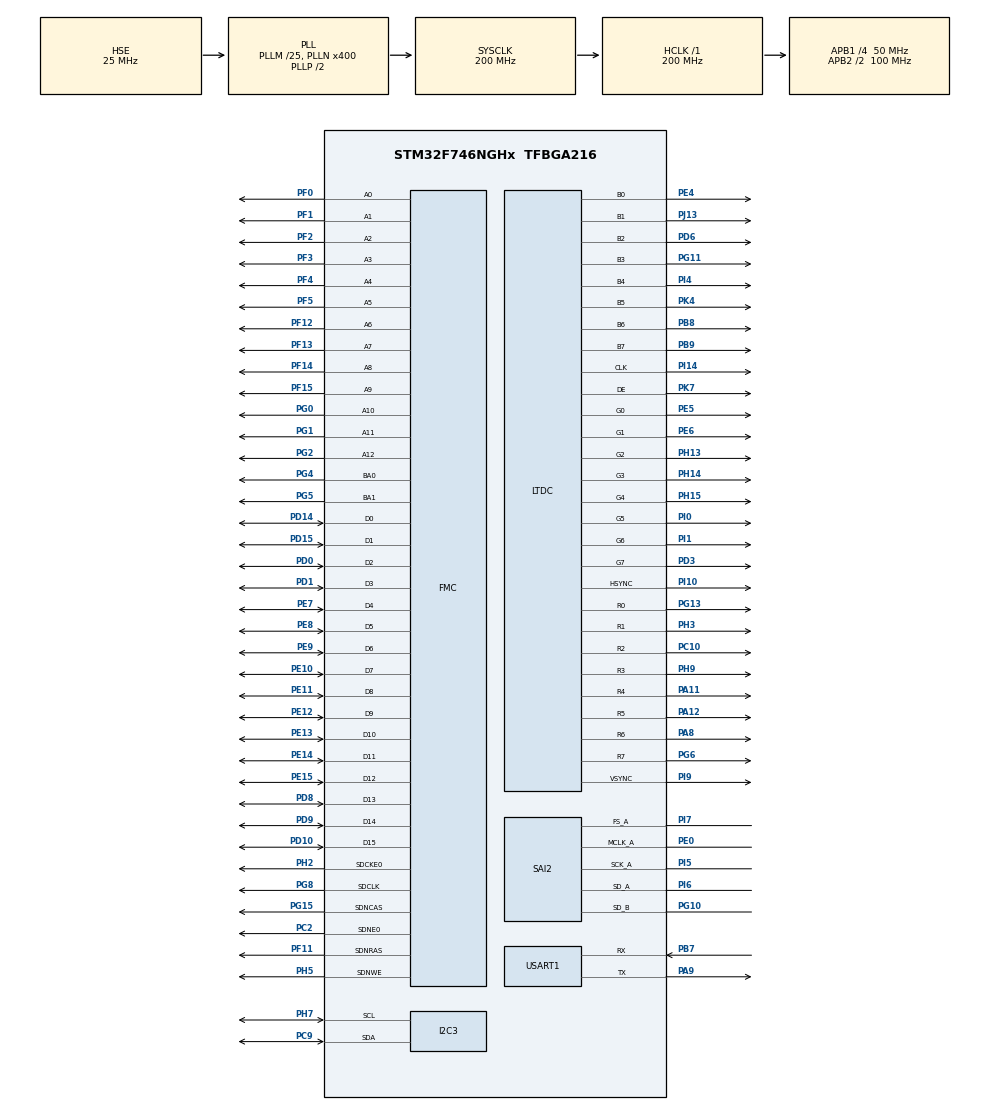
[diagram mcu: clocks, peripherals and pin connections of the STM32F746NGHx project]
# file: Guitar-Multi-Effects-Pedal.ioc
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Dma.Request0=SAI2_A
Dma.Request1=SAI2_B
Dma.SAI2_A.0.Direction=DMA_MEMORY_TO_PERIPH
Dma.SAI2_A.0.FIFOMode=DMA_FIFOMODE_DISABLE
Dma.SAI2_A.0.Instance=DMA2_Stream4
Dma.SAI2_A.0.MemDataAlignment=DMA_MDATAALIGN_BYTE
Dma.SAI2_A.0.MemInc=DMA_MINC_ENABLE
Dma.SAI2_A.0.Mode=DMA_CIRCULAR
Dma.SAI2_A.0.PeriphDataAlignment=DMA_PDATAALIGN_BYTE
Dma.SAI2_A.0.PeriphInc=DMA_PINC_DISABLE
Dma.SAI2_A.0.Priority=DMA_PRIORITY_HIGH
Dma.SAI2_B.1.Direction=DMA_PERIPH_TO_MEMORY
Dma.SAI2_B.1.FIFOMode=DMA_FIFOMODE_DISABLE
Dma.SAI2_B.1.Instance=DMA2_Stream6
Dma.SAI2_B.1.MemDataAlignment=DMA_MDATAALIGN_HALFWORD
Dma.SAI2_B.1.MemInc=DMA_MINC_ENABLE
Dma.SAI2_B.1.Mode=DMA_CIRCULAR
Dma.SAI2_B.1.PeriphDataAlignment=DMA_PDATAALIGN_HALFWORD
Dma.SAI2_B.1.PeriphInc=DMA_PINC_DISABLE
Dma.SAI2_B.1.Priority=DMA_PRIORITY_HIGH
I2C3.Timing=0x00C0EAFF
Mcu.Family=STM32F7
Mcu.Name=STM32F746NGHx
Mcu.Package=TFBGA216
NVIC.DMA2_Stream4_IRQn=true\:0\:0\:false\:false\:true\:false\:true\:true
NVIC.DMA2_Stream6_IRQn=true\:0\:0\:false\:false\:true\:false\:true\:true
NVIC.PriorityGroup=NVIC_PRIORITYGROUP_4
PA11.Mode=RGB888
PA11.Signal=LTDC_R4
PA12.Mode=RGB888
PA12.Signal=LTDC_R5
PA13.Mode=Serial_Wire
PA13.Signal=SYS_JTMS-SWDIO
PA14.Mode=Serial_Wire
PA14.Signal=SYS_JTCK-SWCLK
PA8.Mode=RGB888
PA8.Signal=LTDC_R6
PA9.Mode=Asynchronous
PA9.Signal=USART1_TX
PB7.Mode=Asynchronous
PB7.Signal=USART1_RX
PB8.Mode=RGB888
PB8.Signal=LTDC_B6
PB9.Mode=RGB888
PB9.Signal=LTDC_B7
PC10.Mode=RGB888
PC10.Signal=LTDC_R2
PC14/OSC32_IN.Mode=LSE-External-Oscillator
PC14/OSC32_IN.Signal=RCC_OSC32_IN
PC15/OSC32_OUT.Mode=LSE-External-Oscillator
PC15/OSC32_OUT.Signal=RCC_OSC32_OUT
PC2.Mode=SdramChipSelect1_1
PC2.Signal=FMC_SDNE0
PC9.Mode=I2C
PC9.Signal=I2C3_SDA
PD0.Signal=FMC_D2_DA2
PD1.Signal=FMC_D3_DA3
PD10.Signal=FMC_D15_DA15
PD14.Signal=FMC_D0_DA0
PD15.Signal=FMC_D1_DA1
PD3.Mode=RGB888
PD3.Signal=LTDC_G7
PD6.Mode=RGB888
PD6.Signal=LTDC_B2
PD8.Signal=FMC_D13_DA13
PD9.Signal=FMC_D14_DA14
PE0.Mode=SAI_A_MasterWithClock
PE0.Signal=SAI2_MCLK_A
PE10.Signal=FMC_D7_DA7
PE11.Signal=FMC_D8_DA8
PE12.Signal=FMC_D9_DA9
PE13.Signal=FMC_D10_DA10
PE14.Signal=FMC_D11_DA11
PE15.Signal=FMC_D12_DA12
PE4.Mode=RGB888
PE4.Signal=LTDC_B0
PE5.Mode=RGB888
PE5.Signal=LTDC_G0
PE6.Mode=RGB888
PE6.Signal=LTDC_G1
PE7.Signal=FMC_D4_DA4
PE8.Signal=FMC_D5_DA5
PE9.Signal=FMC_D6_DA6
PF0.Signal=FMC_A0
PF1.Signal=FMC_A1
PF11.Signal=FMC_SDNRAS
PF12.Signal=FMC_A6
PF13.Signal=FMC_A7
PF14.Signal=FMC_A8
PF15.Signal=FMC_A9
PF2.Signal=FMC_A2
PF3.Signal=FMC_A3
PF4.Signal=FMC_A4
PF5.Signal=FMC_A5
PG0.Signal=FMC_A10
PG1.Signal=FMC_A11
PG10.Mode=SAI_B_SyncSlave
PG10.Signal=SAI2_SD_B
PG11.Mode=RGB888
PG11.Signal=LTDC_B3
PG13.Mode=RGB888
PG13.Signal=LTDC_R0
PG15.Signal=FMC_SDNCAS
PG2.Signal=FMC_A12
PG4.Signal=FMC_A14_BA0
PG5.Signal=FMC_A15_BA1
PG6.Mode=RGB888
PG6.Signal=LTDC_R7
PG8.Signal=FMC_SDCLK
PH0/OSC_IN.Mode=HSE-External-Oscillator
PH0/OSC_IN.Signal=RCC_OSC_IN
PH1/OSC_OUT.Mode=HSE-External-Oscillator
PH1/OSC_OUT.Signal=RCC_OSC_OUT
PH13.Mode=RGB888
PH13.Signal=LTDC_G2
PH14.Mode=RGB888
PH14.Signal=LTDC_G3
PH15.Mode=RGB888
PH15.Signal=LTDC_G4
PH2.Mode=SdramChipSelect1_1
PH2.Signal=FMC_SDCKE0
PH3.Mode=RGB888
PH3.Signal=LTDC_R1
PH5.Signal=FMC_SDNWE
PH7.Mode=I2C
PH7.Signal=I2C3_SCL
PH9.Mode=RGB888
PH9.Signal=LTDC_R3
PI0.Mode=RGB888
PI0.Signal=LTDC_G5
PI1.Mode=RGB888
PI1.Signal=LTDC_G6
PI10.Mode=RGB888
PI10.Signal=LTDC_HSYNC
PI14.Mode=RGB888
PI14.Signal=LTDC_CLK
PI4.Mode=RGB888
PI4.Signal=LTDC_B4
PI5.Mode=SAI_A_MasterWithClock
PI5.Signal=SAI2_SCK_A
PI6.Mode=SAI_A_MasterWithClock
PI6.Signal=SAI2_SD_A
PI7.Mode=SAI_A_MasterWithClock
PI7.Signal=SAI2_FS_A
PI9.Mode=RGB888
PI9.Signal=LTDC_VSYNC
PJ13.Mode=RGB888
PJ13.Signal=LTDC_B1
PK4.Mode=RGB888
PK4.Signal=LTDC_B5
PK7.Mode=RGB888
PK7.Signal=LTDC_DE
ProjectManager.HeapSize=0x200
ProjectManager.StackSize=0x400
ProjectManager.TargetToolchain=STM32CubeIDE
RCC.AHBFreq_Value=200000000
RCC.APB1CLKDivider=RCC_HCLK_DIV4
RCC.APB1Freq_Value=50000000
RCC.APB1TimFreq_Value=100000000
RCC.APB2CLKDivider=RCC_HCLK_DIV2
RCC.APB2Freq_Value=100000000
RCC.APB2TimFreq_Value=200000000
RCC.CortexFreq_Value=200000000
RCC.HCLKFreq_Value=200000000
RCC.HSE_VALUE=25000000
RCC.HSI_VALUE=16000000
RCC.PLLI2SN=100
RCC.PLLM=25
RCC.PLLN=400
RCC.PLLSAIN=384
RCC.PLLSAIQ=8
RCC.PLLSAIR=5
RCC.PLLSAIRDiv=RCC_PLLSAIDIVR_8
RCC.PLLSourceVirtual=RCC_PLLSOURCE_HSE
RCC.SYSCLKFreq_VALUE=200000000
RCC.SYSCLKSource=RCC_SYSCLKSOURCE_PLLCLK
RCC.USBFreq_Value=200000000
RCC.VCOOutputFreq_Value=400000000
SAI2.AudioFrequency-SAI_A_MasterWithClock=SAI_AUDIO_FREQUENCY_48K
SAI2.DataSize-SAI_A_MasterWithClock=SAI_DATASIZE_16
SAI2.DataSize-SAI_B_SyncSlave=SAI_DATASIZE_16
SAI2.ErrorAudioFreq-SAI_A_MasterWithClock=-2.34 %
SAI2.FrameLength-SAI_A_MasterWithClock=32
SAI2.FrameLength-SAI_B_SyncSlave=32
SAI2.Instance-SAI_A_MasterWithClock=SAI$Index_Block_A
SAI2.Instance-SAI_B_SyncSlave=SAI$Index_Block_B
SAI2.MClockEnable-SAI_A_MasterWithClock=SAI_MASTERCLOCK_ENABLE
SAI2.RealAudioFreq-SAI_A_MasterWithClock=46.875 KHz
SAI2.VirtualMode-SAI_A_MasterWithClock=VM_MASTER
SAI2.VirtualMode-SAI_B_SyncSlave=VM_SLAVE
SH.FMC_A0.0=FMC_A0,13b-sda1
SH.FMC_A1.0=FMC_A1,13b-sda1
SH.FMC_A10.0=FMC_A10,13b-sda1
SH.FMC_A11.0=FMC_A11,13b-sda1
SH.FMC_A12.0=FMC_A12,13b-sda1
SH.FMC_A14_BA0.0=FMC_BA0,FourSdramBanks1
SH.FMC_A15_BA1.0=FMC_BA1,FourSdramBanks1
SH.FMC_A2.0=FMC_A2,13b-sda1
SH.FMC_A3.0=FMC_A3,13b-sda1
SH.FMC_A4.0=FMC_A4,13b-sda1
SH.FMC_A5.0=FMC_A5,13b-sda1
SH.FMC_A6.0=FMC_A6,13b-sda1
SH.FMC_A7.0=FMC_A7,13b-sda1
SH.FMC_A8.0=FMC_A8,13b-sda1
SH.FMC_A9.0=FMC_A9,13b-sda1
SH.FMC_D0_DA0.0=FMC_D0,sd-16b-d1
SH.FMC_D10_DA10.0=FMC_D10,sd-16b-d1
SH.FMC_D11_DA11.0=FMC_D11,sd-16b-d1
SH.FMC_D12_DA12.0=FMC_D12,sd-16b-d1
SH.FMC_D13_DA13.0=FMC_D13,sd-16b-d1
SH.FMC_D14_DA14.0=FMC_D14,sd-16b-d1
SH.FMC_D15_DA15.0=FMC_D15,sd-16b-d1
SH.FMC_D1_DA1.0=FMC_D1,sd-16b-d1
SH.FMC_D2_DA2.0=FMC_D2,sd-16b-d1
SH.FMC_D3_DA3.0=FMC_D3,sd-16b-d1
SH.FMC_D4_DA4.0=FMC_D4,sd-16b-d1
SH.FMC_D5_DA5.0=FMC_D5,sd-16b-d1
SH.FMC_D6_DA6.0=FMC_D6,sd-16b-d1
SH.FMC_D7_DA7.0=FMC_D7,sd-16b-d1
SH.FMC_D8_DA8.0=FMC_D8,sd-16b-d1
SH.FMC_D9_DA9.0=FMC_D9,sd-16b-d1
SH.FMC_SDCLK.0=FMC_SDCLK,13b-sda1
SH.FMC_SDNCAS.0=FMC_SDNCAS,13b-sda1
SH.FMC_SDNRAS.0=FMC_SDNRAS,13b-sda1
SH.FMC_SDNWE.0=FMC_SDNWE,13b-sda1
USART1.VirtualMode-Asynchronous=VM_ASYNC
VP_DMA2D_VS_DMA2D.Mode=DMA2D_Activate
VP_TIM1_VS_ClockSourceINT.Mode=Internal
board=STM32F746G-DISCO

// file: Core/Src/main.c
/* USER CODE BEGIN Header */
/**
  ******************************************************************************
  * @file           : main.c
  * @brief          : Initializes system, calls Audio_Peripheral_Init(), handles the main loop logic.
  ******************************************************************************
  * @attention
  *
  * Copyright (c) 2024 STMicroelectronics.
  * All rights reserved.
  *
  * This software is licensed under terms that can be found in the LICENSE file
  * in the root directory of this software component.
  * If no LICENSE file comes with this software, it is provided AS-IS.
  *
  ******************************************************************************
  */

/* Pseudocode:
 *
 *  Set up buffers:
 *
 *
 *
 *  CODEC ADC -->  SAI2B (SAI receiving subblock) -> input_buffer[N/4] (16 bit), x_in_temp[N] (32 bit float conversion), x_in[N] input signal block, (DSP happens here), x_out_temp[2*N] circular buffer of output signal, output_buffer[N/4] (16 bit) --> SAI2A (SAI transmitting subblock) --> CODEC DAC
 *
 * Initialize audio input and audio output lines on audio CODEC. Use BSP_AUDIO_OUT_Init and BSP_AUDIO_IN_InitEx function and the following audio devices:  INPUT_DEVICE_INPUT_LINE_1 , OUTPUT_DEVICE_HEADPHONE
 *
 *
 *
 *Buffer Size (bytes)=Number of Samples×Number of Channels×Bytes per Sample
 *
 *
 *
 *
 */
/* USER CODE END Header */
#include "main.h"

/* USER CODE BEGIN Includes */

#include "stm32f7xx_hal.h"
#include "wm8994.h"
#include "stm32746g_discovery_audio.h"
#include <string.h>

/* USER CODE END Includes */

/* USER CODE BEGIN PD */

#define BUFFER_SIZE  512

// Define the SAI handles
SAI_HandleTypeDef hsai_Out;
SAI_HandleTypeDef hsai_In;

// DMA handle
DMA_HandleTypeDef hdma_sai_rx;
DMA_HandleTypeDef hdma_sai_tx;

/* USER CODE END PD */

DMA2D_HandleTypeDef hdma2d;

I2C_HandleTypeDef hi2c3;

LTDC_HandleTypeDef hltdc;

SAI_HandleTypeDef hsai_BlockA2;
SAI_HandleTypeDef hsai_BlockB2;
DMA_HandleTypeDef hdma_sai2_a;
DMA_HandleTypeDef hdma_sai2_b;

TIM_HandleTypeDef htim1;

UART_HandleTypeDef huart1;

SDRAM_HandleTypeDef hsdram1;

/* USER CODE BEGIN PV */
extern SAI_HandleTypeDef haudio_out_sai, haudio_in_sai;

int16_t input_data[BUFFER_SIZE];
int16_t processed_data[BUFFER_SIZE];
int16_t output_data[BUFFER_SIZE];

static volatile int16_t *inBufPtr;
static volatile int16_t *procBufPtr = &processed_data[0];
static volatile int16_t *outBufPtr = &output_data[0];

uint8_t dataReadyFlag;

/* USER CODE END PV */

void SystemClock_Config(void);
void PeriphCommonClock_Config(void);
static void MX_GPIO_Init(void);
static void MX_DMA_Init(void);
static void MX_SAI2_Init(void);
static void MX_USART1_UART_Init(void);
static void MX_TIM1_Init(void);
static void MX_DMA2D_Init(void);
static void MX_LTDC_Init(void);
static void MX_FMC_Init(void);
static void MX_I2C3_Init(void);
/* USER CODE BEGIN PFP */

void processData(int16_t *inBufPtr, int16_t *outBufPtr, uint16_t size);
static void fill_buffer_with_square_wave(int16_t *buf, uint32_t num_samples);

/* USER CODE END PFP */

/* USER CODE BEGIN 0 */
void BSP_AUDIO_IN_HalfTransfer_CallBack()
{
	// Process the first half of the input buffer
		processData(&input_data[0], &processed_data[0], BUFFER_SIZE / 2);
		dataReadyFlag = 1;
}

void BSP_AUDIO_IN_TransferComplete_CallBack()
{
	processData(&input_data[BUFFER_SIZE / 2], &processed_data[BUFFER_SIZE / 2], BUFFER_SIZE / 2);
	dataReadyFlag = 1;
}

void BSP_AUDIO_OUT_HalfTransfer_CallBack()
{
	memcpy(&output_data[0], &processed_data[0], BUFFER_SIZE / 2 * sizeof(int16_t));
}

void BSP_AUDIO_OUT_TransferComplete_CallBack()
{
	memcpy(&output_data[BUFFER_SIZE / 2], &processed_data[BUFFER_SIZE / 2], BUFFER_SIZE / 2 * sizeof(int16_t));
}

/* USER CODE END 0 */

int main(void)
{

  /* MCU Configuration--------------------------------------------------------*/

  /* Reset of all peripherals, Initializes the Flash interface and the Systick. */
  HAL_Init();

  /* Configure the system clock */
  SystemClock_Config();

  /* Configure the peripherals common clocks */
  PeriphCommonClock_Config();

  /* Initialize all configured peripherals */
  MX_GPIO_Init();
  MX_DMA_Init();
  MX_SAI2_Init();
  MX_USART1_UART_Init();
  MX_TIM1_Init();
  MX_DMA2D_Init();
  MX_LTDC_Init();
  MX_FMC_Init();
  MX_I2C3_Init();
  /* USER CODE BEGIN 2 */
  Display_Init();
  if (wm8994_Init(AUDIO_I2C_ADDRESS, INPUT_DEVICE_INPUT_LINE_1 | OUTPUT_DEVICE_HEADPHONE , 80, SAI_AUDIO_FREQUENCY_48K)==0)
  {
	  Display_Draw_Text("Codec initialized", 0, 10);
  }
  HAL_Delay(50);
  // Start audio input (SAI Receive) and output (SAI Transmit) using DMA
 // HAL_StatusTypeDef statusTx = HAL_SAI_Transmit_DMA(&hsai_BlockA2, (uint8_t *)output_data, BUFFER_SIZE);
 // HAL_StatusTypeDef statusRx = HAL_SAI_Receive_DMA(&hsai_BlockB2, (uint8_t *)input_data, BUFFER_SIZE);

   //Display_Draw_Text("Codec is not recording", 0, 60);

 /* if (HAL_SAI_Receive_DMA(&hsai_BlockB2, (uint8_t *)input_data, BUFFER_SIZE) == HAL_OK)
  {
	  Display_Draw_Text("SAI Recieve Setup", 0, 30);
  }
  else{
	  Display_Draw_Text("SAI Recieve Not Setup", 0, 30);
  }
*/

  if (HAL_SAI_Transmit_DMA(&hsai_BlockA2, (uint8_t *)output_data, BUFFER_SIZE) == HAL_OK)
  {
	  Display_Draw_Text("SAI Transmit Setup", 0, 50);
  }
  else{
	  Display_Draw_Text("SAI Transmit Not Setup", 0, 50);
  }

  dataReadyFlag = 0;

  fill_buffer_with_square_wave(input_data, BUFFER_SIZE);

  /* USER CODE END 2 */

  /* Infinite loop */
  /* USER CODE BEGIN WHILE */
  while (1)
  {
	  if (dataReadyFlag){

		  // Reset the flag after processing
	dataReadyFlag = 0;

	  }

    /* USER CODE END WHILE */

  }
}

void SystemClock_Config(void)
{
  RCC_OscInitTypeDef RCC_OscInitStruct = {0};
  RCC_ClkInitTypeDef RCC_ClkInitStruct = {0};

  /** Configure LSE Drive Capability
  */
  HAL_PWR_EnableBkUpAccess();

  /** Configure the main internal regulator output voltage
  */
  __HAL_RCC_PWR_CLK_ENABLE();
  __HAL_PWR_VOLTAGESCALING_CONFIG(PWR_REGULATOR_VOLTAGE_SCALE1);

  /** Initializes the RCC Oscillators according to the specified parameters
  * in the RCC_OscInitTypeDef structure.
  */
  RCC_OscInitStruct.OscillatorType = RCC_OSCILLATORTYPE_HSE;
  RCC_OscInitStruct.HSEState = RCC_HSE_ON;
  RCC_OscInitStruct.PLL.PLLState = RCC_PLL_ON;
  RCC_OscInitStruct.PLL.PLLSource = RCC_PLLSOURCE_HSE;
  RCC_OscInitStruct.PLL.PLLM = 25;
  RCC_OscInitStruct.PLL.PLLN = 400;
  RCC_OscInitStruct.PLL.PLLP = RCC_PLLP_DIV2;
  RCC_OscInitStruct.PLL.PLLQ = 2;
  if (HAL_RCC_OscConfig(&RCC_OscInitStruct) != HAL_OK)
  {
    Error_Handler();
  }

  /** Activate the Over-Drive mode
  */
  if (HAL_PWREx_EnableOverDrive() != HAL_OK)
  {
    Error_Handler();
  }

  /** Initializes the CPU, AHB and APB buses clocks
  */
  RCC_ClkInitStruct.ClockType = RCC_CLOCKTYPE_HCLK|RCC_CLOCKTYPE_SYSCLK
                              |RCC_CLOCKTYPE_PCLK1|RCC_CLOCKTYPE_PCLK2;
  RCC_ClkInitStruct.SYSCLKSource = RCC_SYSCLKSOURCE_PLLCLK;
  RCC_ClkInitStruct.AHBCLKDivider = RCC_SYSCLK_DIV1;
  RCC_ClkInitStruct.APB1CLKDivider = RCC_HCLK_DIV4;
  RCC_ClkInitStruct.APB2CLKDivider = RCC_HCLK_DIV2;

  if (HAL_RCC_ClockConfig(&RCC_ClkInitStruct, FLASH_LATENCY_6) != HAL_OK)
  {
    Error_Handler();
  }
}

void PeriphCommonClock_Config(void)
{
  RCC_PeriphCLKInitTypeDef PeriphClkInitStruct = {0};

  /** Initializes the peripherals clock
  */
  PeriphClkInitStruct.PeriphClockSelection = RCC_PERIPHCLK_LTDC|RCC_PERIPHCLK_SAI2;
  PeriphClkInitStruct.PLLSAI.PLLSAIN = 384;
  PeriphClkInitStruct.PLLSAI.PLLSAIR = 5;
  PeriphClkInitStruct.PLLSAI.PLLSAIQ = 8;
  PeriphClkInitStruct.PLLSAI.PLLSAIP = RCC_PLLSAIP_DIV2;
  PeriphClkInitStruct.PLLSAIDivQ = 1;
  PeriphClkInitStruct.PLLSAIDivR = RCC_PLLSAIDIVR_8;
  PeriphClkInitStruct.Sai2ClockSelection = RCC_SAI2CLKSOURCE_PLLSAI;
  if (HAL_RCCEx_PeriphCLKConfig(&PeriphClkInitStruct) != HAL_OK)
  {
    Error_Handler();
  }
}

static void MX_DMA2D_Init(void)
{

  hdma2d.Instance = DMA2D;
  hdma2d.Init.Mode = DMA2D_M2M;
  hdma2d.Init.ColorMode = DMA2D_OUTPUT_ARGB8888;
  hdma2d.Init.OutputOffset = 0;
  hdma2d.LayerCfg[1].InputOffset = 0;
  hdma2d.LayerCfg[1].InputColorMode = DMA2D_INPUT_ARGB8888;
  hdma2d.LayerCfg[1].AlphaMode = DMA2D_NO_MODIF_ALPHA;
  hdma2d.LayerCfg[1].InputAlpha = 0;
  if (HAL_DMA2D_Init(&hdma2d) != HAL_OK)
  {
    Error_Handler();
  }
  if (HAL_DMA2D_ConfigLayer(&hdma2d, 1) != HAL_OK)
  {
    Error_Handler();
  }

}

static void MX_I2C3_Init(void)
{

  hi2c3.Instance = I2C3;
  hi2c3.Init.Timing = 0x00C0EAFF;
  hi2c3.Init.OwnAddress1 = 0;
  hi2c3.Init.AddressingMode = I2C_ADDRESSINGMODE_7BIT;
  hi2c3.Init.DualAddressMode = I2C_DUALADDRESS_DISABLE;
  hi2c3.Init.OwnAddress2 = 0;
  hi2c3.Init.OwnAddress2Masks = I2C_OA2_NOMASK;
  hi2c3.Init.GeneralCallMode = I2C_GENERALCALL_DISABLE;
  hi2c3.Init.NoStretchMode = I2C_NOSTRETCH_DISABLE;
  if (HAL_I2C_Init(&hi2c3) != HAL_OK)
  {
    Error_Handler();
  }

  /** Configure Analogue filter
  */
  if (HAL_I2CEx_ConfigAnalogFilter(&hi2c3, I2C_ANALOGFILTER_ENABLE) != HAL_OK)
  {
    Error_Handler();
  }

  /** Configure Digital filter
  */
  if (HAL_I2CEx_ConfigDigitalFilter(&hi2c3, 0) != HAL_OK)
  {
    Error_Handler();
  }

}

static void MX_LTDC_Init(void)
{

  LTDC_LayerCfgTypeDef pLayerCfg = {0};
  LTDC_LayerCfgTypeDef pLayerCfg1 = {0};

  hltdc.Instance = LTDC;
  hltdc.Init.HSPolarity = LTDC_HSPOLARITY_AL;
  hltdc.Init.VSPolarity = LTDC_VSPOLARITY_AL;
  hltdc.Init.DEPolarity = LTDC_DEPOLARITY_AL;
  hltdc.Init.PCPolarity = LTDC_PCPOLARITY_IPC;
  hltdc.Init.HorizontalSync = 7;
  hltdc.Init.VerticalSync = 3;
  hltdc.Init.AccumulatedHBP = 14;
  hltdc.Init.AccumulatedVBP = 5;
  hltdc.Init.AccumulatedActiveW = 654;
  hltdc.Init.AccumulatedActiveH = 485;
  hltdc.Init.TotalWidth = 660;
  hltdc.Init.TotalHeigh = 487;
  hltdc.Init.Backcolor.Blue = 0;
  hltdc.Init.Backcolor.Green = 0;
  hltdc.Init.Backcolor.Red = 0;
  if (HAL_LTDC_Init(&hltdc) != HAL_OK)
  {
    Error_Handler();
  }
  pLayerCfg.WindowX0 = 0;
  pLayerCfg.WindowX1 = 0;
  pLayerCfg.WindowY0 = 0;
  pLayerCfg.WindowY1 = 0;
  pLayerCfg.PixelFormat = LTDC_PIXEL_FORMAT_ARGB8888;
  pLayerCfg.Alpha = 0;
  pLayerCfg.Alpha0 = 0;
  pLayerCfg.BlendingFactor1 = LTDC_BLENDING_FACTOR1_CA;
  pLayerCfg.BlendingFactor2 = LTDC_BLENDING_FACTOR2_CA;
  pLayerCfg.FBStartAdress = 0;
  pLayerCfg.ImageWidth = 0;
  pLayerCfg.ImageHeight = 0;
  pLayerCfg.Backcolor.Blue = 0;
  pLayerCfg.Backcolor.Green = 0;
  pLayerCfg.Backcolor.Red = 0;
  if (HAL_LTDC_ConfigLayer(&hltdc, &pLayerCfg, 0) != HAL_OK)
  {
    Error_Handler();
  }
  pLayerCfg1.WindowX0 = 0;
  pLayerCfg1.WindowX1 = 0;
  pLayerCfg1.WindowY0 = 0;
  pLayerCfg1.WindowY1 = 0;
  pLayerCfg1.PixelFormat = LTDC_PIXEL_FORMAT_ARGB8888;
  pLayerCfg1.Alpha = 0;
  pLayerCfg1.Alpha0 = 0;
  pLayerCfg1.BlendingFactor1 = LTDC_BLENDING_FACTOR1_CA;
  pLayerCfg1.BlendingFactor2 = LTDC_BLENDING_FACTOR2_CA;
  pLayerCfg1.FBStartAdress = 0;
  pLayerCfg1.ImageWidth = 0;
  pLayerCfg1.ImageHeight = 0;
  pLayerCfg1.Backcolor.Blue = 0;
  pLayerCfg1.Backcolor.Green = 0;
  pLayerCfg1.Backcolor.Red = 0;
  if (HAL_LTDC_ConfigLayer(&hltdc, &pLayerCfg1, 1) != HAL_OK)
  {
    Error_Handler();
  }

}

static void MX_SAI2_Init(void)
{

  hsai_BlockA2.Instance = SAI2_Block_A;
  hsai_BlockA2.Init.Protocol = SAI_FREE_PROTOCOL;
  hsai_BlockA2.Init.AudioMode = SAI_MODEMASTER_TX;
  hsai_BlockA2.Init.DataSize = SAI_DATASIZE_16;
  hsai_BlockA2.Init.FirstBit = SAI_FIRSTBIT_MSB;
  hsai_BlockA2.Init.ClockStrobing = SAI_CLOCKSTROBING_FALLINGEDGE;
  hsai_BlockA2.Init.Synchro = SAI_ASYNCHRONOUS;
  hsai_BlockA2.Init.OutputDrive = SAI_OUTPUTDRIVE_DISABLE;
  hsai_BlockA2.Init.NoDivider = SAI_MASTERDIVIDER_ENABLE;
  hsai_BlockA2.Init.FIFOThreshold = SAI_FIFOTHRESHOLD_EMPTY;
  hsai_BlockA2.Init.AudioFrequency = SAI_AUDIO_FREQUENCY_48K;
  hsai_BlockA2.Init.SynchroExt = SAI_SYNCEXT_DISABLE;
  hsai_BlockA2.Init.MonoStereoMode = SAI_STEREOMODE;
  hsai_BlockA2.Init.CompandingMode = SAI_NOCOMPANDING;
  hsai_BlockA2.Init.TriState = SAI_OUTPUT_NOTRELEASED;
  hsai_BlockA2.FrameInit.FrameLength = 32;
  hsai_BlockA2.FrameInit.ActiveFrameLength = 1;
  hsai_BlockA2.FrameInit.FSDefinition = SAI_FS_STARTFRAME;
  hsai_BlockA2.FrameInit.FSPolarity = SAI_FS_ACTIVE_LOW;
  hsai_BlockA2.FrameInit.FSOffset = SAI_FS_FIRSTBIT;
  hsai_BlockA2.SlotInit.FirstBitOffset = 0;
  hsai_BlockA2.SlotInit.SlotSize = SAI_SLOTSIZE_DATASIZE;
  hsai_BlockA2.SlotInit.SlotNumber = 1;
  hsai_BlockA2.SlotInit.SlotActive = 0x00000000;
  if (HAL_SAI_Init(&hsai_BlockA2) != HAL_OK)
  {
    Error_Handler();
  }
  hsai_BlockB2.Instance = SAI2_Block_B;
  hsai_BlockB2.Init.Protocol = SAI_FREE_PROTOCOL;
  hsai_BlockB2.Init.AudioMode = SAI_MODESLAVE_RX;
  hsai_BlockB2.Init.DataSize = SAI_DATASIZE_16;
  hsai_BlockB2.Init.FirstBit = SAI_FIRSTBIT_MSB;
  hsai_BlockB2.Init.ClockStrobing = SAI_CLOCKSTROBING_FALLINGEDGE;
  hsai_BlockB2.Init.Synchro = SAI_SYNCHRONOUS;
  hsai_BlockB2.Init.OutputDrive = SAI_OUTPUTDRIVE_DISABLE;
  hsai_BlockB2.Init.FIFOThreshold = SAI_FIFOTHRESHOLD_EMPTY;
  hsai_BlockB2.Init.SynchroExt = SAI_SYNCEXT_DISABLE;
  hsai_BlockB2.Init.MonoStereoMode = SAI_STEREOMODE;
  hsai_BlockB2.Init.CompandingMode = SAI_NOCOMPANDING;
  hsai_BlockB2.Init.TriState = SAI_OUTPUT_NOTRELEASED;
  hsai_BlockB2.FrameInit.FrameLength = 32;
  hsai_BlockB2.FrameInit.ActiveFrameLength = 1;
  hsai_BlockB2.FrameInit.FSDefinition = SAI_FS_STARTFRAME;
  hsai_BlockB2.FrameInit.FSPolarity = SAI_FS_ACTIVE_LOW;
  hsai_BlockB2.FrameInit.FSOffset = SAI_FS_FIRSTBIT;
  hsai_BlockB2.SlotInit.FirstBitOffset = 0;
  hsai_BlockB2.SlotInit.SlotSize = SAI_SLOTSIZE_DATASIZE;
  hsai_BlockB2.SlotInit.SlotNumber = 1;
  hsai_BlockB2.SlotInit.SlotActive = 0x00000000;
  if (HAL_SAI_Init(&hsai_BlockB2) != HAL_OK)
  {
    Error_Handler();
  }

}

static void MX_TIM1_Init(void)
{

  TIM_ClockConfigTypeDef sClockSourceConfig = {0};
  TIM_MasterConfigTypeDef sMasterConfig = {0};

  htim1.Instance = TIM1;
  htim1.Init.Prescaler = 0;
  htim1.Init.CounterMode = TIM_COUNTERMODE_UP;
  htim1.Init.Period = 65535;
  htim1.Init.ClockDivision = TIM_CLOCKDIVISION_DIV1;
  htim1.Init.RepetitionCounter = 0;
  htim1.Init.AutoReloadPreload = TIM_AUTORELOAD_PRELOAD_DISABLE;
  if (HAL_TIM_Base_Init(&htim1) != HAL_OK)
  {
    Error_Handler();
  }
  sClockSourceConfig.ClockSource = TIM_CLOCKSOURCE_INTERNAL;
  if (HAL_TIM_ConfigClockSource(&htim1, &sClockSourceConfig) != HAL_OK)
  {
    Error_Handler();
  }
  sMasterConfig.MasterOutputTrigger = TIM_TRGO_RESET;
  sMasterConfig.MasterOutputTrigger2 = TIM_TRGO2_RESET;
  sMasterConfig.MasterSlaveMode = TIM_MASTERSLAVEMODE_DISABLE;
  if (HAL_TIMEx_MasterConfigSynchronization(&htim1, &sMasterConfig) != HAL_OK)
  {
    Error_Handler();
  }

}

static void MX_USART1_UART_Init(void)
{

  huart1.Instance = USART1;
  huart1.Init.BaudRate = 115200;
  huart1.Init.WordLength = UART_WORDLENGTH_8B;
  huart1.Init.StopBits = UART_STOPBITS_1;
  huart1.Init.Parity = UART_PARITY_NONE;
  huart1.Init.Mode = UART_MODE_TX_RX;
  huart1.Init.HwFlowCtl = UART_HWCONTROL_NONE;
  huart1.Init.OverSampling = UART_OVERSAMPLING_16;
  huart1.Init.OneBitSampling = UART_ONE_BIT_SAMPLE_DISABLE;
  huart1.AdvancedInit.AdvFeatureInit = UART_ADVFEATURE_NO_INIT;
  if (HAL_UART_Init(&huart1) != HAL_OK)
  {
    Error_Handler();
  }

}

static void MX_DMA_Init(void)
{

  /* DMA controller clock enable */
  __HAL_RCC_DMA2_CLK_ENABLE();

  /* DMA interrupt init */
  /* DMA2_Stream4_IRQn interrupt configuration */
  HAL_NVIC_SetPriority(DMA2_Stream4_IRQn, 0, 0);
  HAL_NVIC_EnableIRQ(DMA2_Stream4_IRQn);
  /* DMA2_Stream6_IRQn interrupt configuration */
  HAL_NVIC_SetPriority(DMA2_Stream6_IRQn, 0, 0);
  HAL_NVIC_EnableIRQ(DMA2_Stream6_IRQn);

}

/* FMC initialization function */
static void MX_FMC_Init(void)
{

  FMC_SDRAM_TimingTypeDef SdramTiming = {0};

  /** Perform the SDRAM1 memory initialization sequence
  */
  hsdram1.Instance = FMC_SDRAM_DEVICE;
  /* hsdram1.Init */
  hsdram1.Init.SDBank = FMC_SDRAM_BANK1;
  hsdram1.Init.ColumnBitsNumber = FMC_SDRAM_COLUMN_BITS_NUM_8;
  hsdram1.Init.RowBitsNumber = FMC_SDRAM_ROW_BITS_NUM_13;
  hsdram1.Init.MemoryDataWidth = FMC_SDRAM_MEM_BUS_WIDTH_16;
  hsdram1.Init.InternalBankNumber = FMC_SDRAM_INTERN_BANKS_NUM_4;
  hsdram1.Init.CASLatency = FMC_SDRAM_CAS_LATENCY_1;
  hsdram1.Init.WriteProtection = FMC_SDRAM_WRITE_PROTECTION_DISABLE;
  hsdram1.Init.SDClockPeriod = FMC_SDRAM_CLOCK_DISABLE;
  hsdram1.Init.ReadBurst = FMC_SDRAM_RBURST_DISABLE;
  hsdram1.Init.ReadPipeDelay = FMC_SDRAM_RPIPE_DELAY_0;
  /* SdramTiming */
  SdramTiming.LoadToActiveDelay = 16;
  SdramTiming.ExitSelfRefreshDelay = 16;
  SdramTiming.SelfRefreshTime = 16;
  SdramTiming.RowCycleDelay = 16;
  SdramTiming.WriteRecoveryTime = 16;
  SdramTiming.RPDelay = 16;
  SdramTiming.RCDDelay = 16;

  if (HAL_SDRAM_Init(&hsdram1, &SdramTiming) != HAL_OK)
  {
    Error_Handler( );
  }

}

static void MX_GPIO_Init(void)
{

  /* GPIO Ports Clock Enable */
  __HAL_RCC_GPIOE_CLK_ENABLE();
  __HAL_RCC_GPIOB_CLK_ENABLE();
  __HAL_RCC_GPIOA_CLK_ENABLE();
  __HAL_RCC_GPIOG_CLK_ENABLE();
  __HAL_RCC_GPIOJ_CLK_ENABLE();
  __HAL_RCC_GPIOD_CLK_ENABLE();
  __HAL_RCC_GPIOC_CLK_ENABLE();
  __HAL_RCC_GPIOI_CLK_ENABLE();
  __HAL_RCC_GPIOK_CLK_ENABLE();
  __HAL_RCC_GPIOF_CLK_ENABLE();
  __HAL_RCC_GPIOH_CLK_ENABLE();

}

/* USER CODE BEGIN 4 */

void processData(int16_t *inBufPtr, int16_t *outBufPtr, uint16_t size) {
    static float leftIn, leftOut;
    static float rightIn, rightOut;

    // Loop through the buffer for stereo channels (left and right)
    for (uint16_t n = 0; n < size; n += 2) {

        // --- Left Channel Processing ---

        // Get ADC input for left channel and convert to float
    	leftIn = INT16_TO_FLOAT(inBufPtr[n]);
        if (leftIn > 1.0f) {
            leftIn -= 2.0f;  // Example of processing, could be customized
        }

        // Compute new output sample for left channel
        leftOut = leftIn; // Example: no processing, just pass-through

        // Convert float back to signed int and set output buffer for DAC
        outBufPtr[n] = FLOAT_TO_INT16(leftOut);

        // --- Right Channel Processing ---

        // Get ADC input for right channel and convert to float
        rightIn = INT16_TO_FLOAT(inBufPtr[n + 1]);
        if (rightIn > 1.0f) {
            rightIn -= 2.0f;  // Example of processing, could be customized
        }

        // Compute new output sample for right channel
        rightOut = rightIn; // Example: no processing, just pass-through

        // Convert float back to signed int and set output buffer for DAC
        outBufPtr[n + 1] = FLOAT_TO_INT16(rightOut);
    }

    dataReadyFlag = 0;
}

static void fill_buffer_with_square_wave(int16_t *buf, uint32_t num_samples)
{
    // Fill up a 100 Hz square wave
    // 48 kHz sample rate -> 480 samples in 100 Hz -> toggle every 240 samples
    int toggle_period = 240;
    int count = 0;
    int wave_state = 1;
    int magnitude = 30000;

    for (int i = 0; i < num_samples; i++)
    {
        // Set the buffer value based on the wave state
        buf[i] = magnitude * wave_state;

        count++;
        if (count >= toggle_period)
        {
            count = 0;
            wave_state = wave_state * (-1);  // Toggle the wave state between 1 and -1
        }
    }
}

/* USER CODE END 4 */

void Error_Handler(void)
{
  __disable_irq();
  while (1)
  {
  }
}
